# STM32WB05 register map
File version: 1.0
CPU: CM0+ r0p0, little endian, MPU, no FPU, 2 interrupt priority bits
Registers are 32-bit, read-write, reset 0x0 unless marked. A register's access mark holds for its fields unless they carry their own. Offsets are from the block's base; [hi:lo] are bit positions.

## RNG
Base 0x48600000
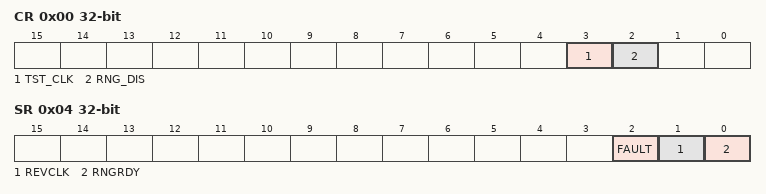
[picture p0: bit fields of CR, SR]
0x00 CR — RNG_CR register
  [3] TST_CLK — RNG Test Clock bit.
  [2] RNG_DIS — RNG Disable bit.
0x04 SR — RNG_SR register
  [2] FAULT — Fault Reveal bit.
  [1] REVCLK ro — RNGCLK Clock Reveal bit.
  [0] RNGRDY ro — New Random Value Ready.
0x08 VAL ro — RNG_VAL register
  [15:0] RANDOM_VALUE

## GLOBALSTATMACH
Base 0x200000C0
0x00 WORD0
  [31:0] RadioConfigPtr — Radio Configuration address Pointer.
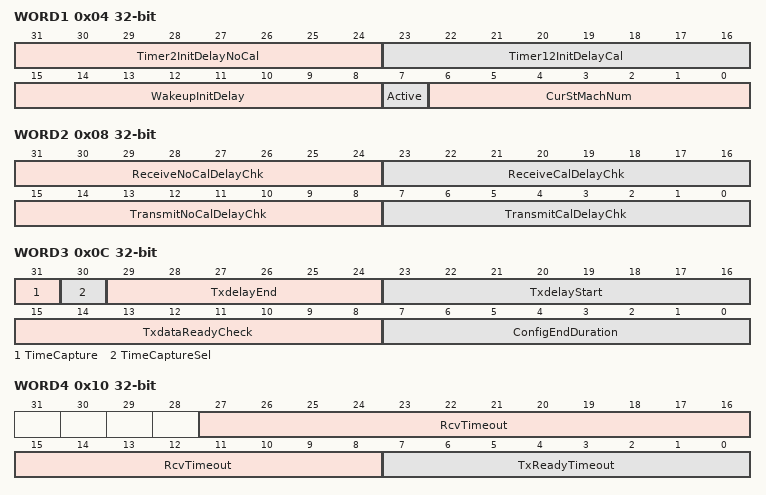
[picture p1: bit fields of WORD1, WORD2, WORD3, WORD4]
0x04 WORD1
  [31:24] Timer2InitDelayNoCal — Delay between Timer2 trig event on Sequencer and RX/TX request sending to the Radio FSM.
  [23:16] Timer12InitDelayCal — Delay between Timer1 or Timer2 trig event on Sequencer and RX/TX request sending to the Radio FSM.
  [15:8] WakeupInitDelay — Delay between wakeup timer trig event on Sequencer and RX/TX request sending to the Radio FSM.
  [7] Active — Must be at '1' when the trig event (Wakeup Timer, Timer1 or Timer2) occurs to starts a Bluetooth LE link layer sequence.
  [6:0] CurStMachNum — current connection machine number.
0x08 WORD2
  [31:24] ReceiveNoCalDelayChk — Delay between RX request sent to the Radio FSM and the start pulse to the receive block.
  [23:16] ReceiveCalDelayChk — Delay between RX request sent to the Radio FSM and the start pulse sent to the receive block.
  [15:8] TransmitNoCalDelayChk — Delay between TX request sent to the Radio FSM and the start pulse to the transmit block.
  [7:0] TransmitCalDelayChk — Delay between TX request sent to the Radio FSM and the start pulse sent to the transmit block.
0x0C WORD3
  [31] TimeCapture — - 0: No capture is requested to monitor the Bluetooth LE sequence.
  [30] TimeCaptureSel — - 0: the captured time (absolute time) corresponds to the end of 1st INIT step in the sequence (InitDelay timeout event).
  [29:24] TxdelayEnd — Delay added between the last bit transmission to the modulator and the end of transmission information for the Sequencer.
  [23:16] TxdelayStart — Delay added between the moment the Radio FSM is in TX mode (PA ramp up done and power present on the antenna) and the first bit transmission to the modulator.
  [15:8] TxdataReadyCheck — Duration for the Sequencer to get the TxDataReady and DataPtr information in TxRxPack table.
  [7:0] ConfigEndDuration — Duration for the Sequencer to execute the final configuration.
0x10 WORD4
  [27:8] RcvTimeout — Receive window timeout.
  [7:0] TxReadyTimeout — Transmission ready timeout.
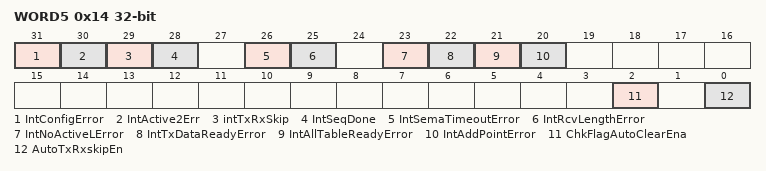
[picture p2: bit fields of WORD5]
0x14 WORD5
  [31] IntConfigError — Configuration error interrupt enable.
  [30] IntActive2Err — not in ACTIVE2 information from Radio FSM received on time interrupt enable.
  [29] intTxRxSkip — Transmission or reception skip interrupt enable.
  [28] IntSeqDone — Sequencer end of task interrupt enable.
  [26] IntSemaTimeoutError — Semaphore timeout error interrupt enable.
  [25] IntRcvLengthError — Too long received payload length interrupt enable.
  [23] IntNoActiveLError — Active bit low value reading interrupt enable.
  [22] IntTxDataReadyError — Transmission data payload ready error interrupt enable.
  [21] IntAllTableReadyError — All table ready error interrupt enable.
  [20] IntAddPointError — Address pointer error interrupt enable.
  [2] ChkFlagAutoClearEna — Active bit Auto Clear Enable.
  [0] AutoTxRxskipEn — Automatic transfer (TX or RX) skip enable.
0x18 WORD6
  [6:0] DefaultAntennaID — Default Antenna ID corresponding to the number of the antenna used to receive/transmit:

## RADIO_CONTROL
Base 0x60001000
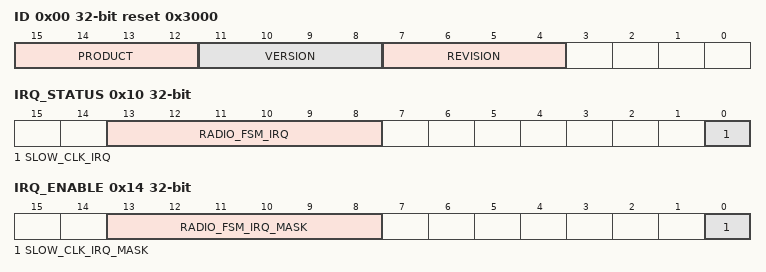
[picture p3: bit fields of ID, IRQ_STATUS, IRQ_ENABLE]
0x00 ID ro reset 0x3000 — RADIO_CONTROL_ID register
  [15:12] PRODUCT — incremented on major features add-on like new Bluetooth LE SIG version support
  [11:8] VERSION — Cut Number
  [7:4] REVISION — Incremented for metal fix version
0x04 CLK32COUNT_REG reset 0x17
  [8:0] SLOW_COUNT — program the window length (in slow clock period) for slow clock measurement.
0x08 CLK32PERIOD_REG ro
  [18:0] SLOW_PERIOD — indicates slow clock period information.
0x0C CLK32FREQUENCY_REG ro
  [26:0] SLOW_FREQUENCY — value equal to (2^39/ SLOW_PERIOD).
0x10 IRQ_STATUS — RADIO_CONTROL_IRQ_STATUS register
  [13:8] RADIO_FSM_IRQ — Radio FSM interrupt status (aka RfFsm_event_irq).
  [0] SLOW_CLK_IRQ — slow clock measurement end of calculation interrupt status
0x14 IRQ_ENABLE — RADIO_CONTROL_IRQ_ENABLE register
  [13:8] RADIO_FSM_IRQ_MASK — mask for each RfFsm_event (Radio FSM) interrupt.
  [0] SLOW_CLK_IRQ_MASK — mask slow clock measurement interrupt
